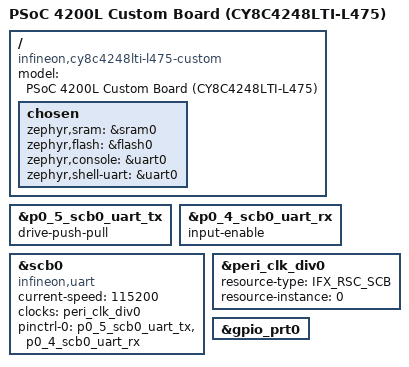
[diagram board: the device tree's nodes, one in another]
/dts-v1/;
#include <arm/infineon/psoc4/mpns/cy8c4248lti_l475.dtsi>
#include <arm/infineon/psoc4/psoc4200l/system_clocks.dtsi>
#include <zephyr/dt-bindings/clock/ifx_clock_source_psoc4xx.h>

/ {
	model = "PSoC 4200L Custom Board (CY8C4248LTI-L475)";
	compatible = "infineon,cy8c4248lti-l475-custom", "infineon,psoc4200l";

	chosen {
		zephyr,sram = &sram0;
		zephyr,flash = &flash0;
		zephyr,console = &uart0;
		zephyr,shell-uart = &uart0;
	};
};

/* Configure pin drive modes */
&p0_5_scb0_uart_tx {
	drive-push-pull;
};

&p0_4_scb0_uart_rx {
	input-enable;
};

/* Use SCB0 as UART console */
uart0: &scb0 {
	compatible = "infineon,uart";
	status = "okay";
	current-speed = <115200>;
	clocks = <&peri_clk_div0>;
	pinctrl-0 = <&p0_5_scb0_uart_tx &p0_4_scb0_uart_rx>;
	pinctrl-names = "default";
};

&peri_clk_div0 {
	status = "okay";
	resource-type = <IFX_RSC_SCB>;
	resource-instance = <0>;
};

&gpio_prt0 {
	status = "okay";
};
